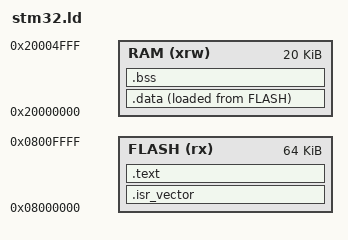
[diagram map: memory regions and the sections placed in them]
MEMORY
{
  FLASH (rx) : ORIGIN = 0x08000000, LENGTH = 64K
  RAM (xrw)  : ORIGIN = 0x20000000, LENGTH = 20K
}
SECTIONS
{
  .isr_vector : { KEEP(*(.isr_vector)) } > FLASH
  .text : { *(.text) } > FLASH
  .data : { *(.data) } > RAM AT > FLASH
  .bss : { *(.bss) } > RAM
}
